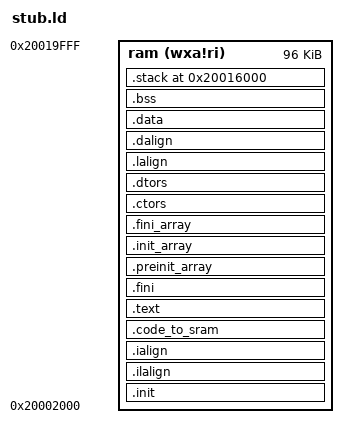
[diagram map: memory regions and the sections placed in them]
OUTPUT_ARCH( "riscv" )

ENTRY( _start )

MEMORY
{
    ram   (wxa!ri) : ORIGIN = 0x20002000, LENGTH = 96K
}


SECTIONS
{
  __stack_size = 16K;

  .init           :
  {
    KEEP (*(SORT_NONE(.init)))
  } >ram

  .ilalign         :
  {
    . = ALIGN(4);
    PROVIDE( _ilm_lma = . );
  } >ram

  .ialign         :
  {
    PROVIDE( _ilm = . );
  } >ram

  _sicode = LOADADDR(.code_to_sram);
  .code_to_sram :
  {
    . = ALIGN(4);
    _scode = .;
    _ecode = .;
  } >ram

  .text           :
  {
    *(.rodata .rodata.*)
    *(.text.unlikely .text.unlikely.*)
    *(.text.startup .text.startup.*)
    *(.text .text.*)
    *(.gnu.linkonce.t.*)
    *(.srodata .srodata.*)
  } >ram

  .fini           :
  {
    KEEP (*(SORT_NONE(.fini)))
  } >ram

  . = ALIGN(4);

  PROVIDE (__etext = .);
  PROVIDE (_etext = .);/*0x80022c8*/
  PROVIDE (etext = .);/*0x80022c8*/
  PROVIDE( _eilm = . );

  .preinit_array  :
  {
    PROVIDE_HIDDEN (__preinit_array_start = .);
    KEEP (*(.preinit_array))
    PROVIDE_HIDDEN (__preinit_array_end = .);
  } >ram

  .init_array     :
  {
    PROVIDE_HIDDEN (__init_array_start = .);
    KEEP (*(SORT_BY_INIT_PRIORITY(.init_array.*) SORT_BY_INIT_PRIORITY(.ctors.*)))
    KEEP (*(.init_array EXCLUDE_FILE (*crtbegin.o *crtbegin?.o *crtend.o *crtend?.o ) .ctors))
    PROVIDE_HIDDEN (__init_array_end = .);
  } >ram

  .fini_array     :
  {
    PROVIDE_HIDDEN (__fini_array_start = .);
    KEEP (*(SORT_BY_INIT_PRIORITY(.fini_array.*) SORT_BY_INIT_PRIORITY(.dtors.*)))
    KEEP (*(.fini_array EXCLUDE_FILE (*crtbegin.o *crtbegin?.o *crtend.o *crtend?.o ) .dtors))
    PROVIDE_HIDDEN (__fini_array_end = .);
  } >ram

  .ctors          :
  {
    /* gcc uses crtbegin.o to find the start of
       the constructors, so we make sure it is
       first.  Because this is a wildcard, it
       doesn't matter if the user does not
       actually link against crtbegin.o; the
       linker won't look for a file to match a
       wildcard.  The wildcard also means that it
       doesn't matter which directory crtbegin.o
       is in.  */
    KEEP (*crtbegin.o(.ctors))
    KEEP (*crtbegin?.o(.ctors))
    /* We don't want to include the .ctor section from
       the crtend.o file until after the sorted ctors.
       The .ctor section from the crtend file contains the
       end of ctors marker and it must be last */
    KEEP (*(EXCLUDE_FILE (*crtend.o *crtend?.o ) .ctors))
    KEEP (*(SORT(.ctors.*)))
    KEEP (*(.ctors))
  } >ram

  .dtors          :
  {
    KEEP (*crtbegin.o(.dtors))
    KEEP (*crtbegin?.o(.dtors))
    KEEP (*(EXCLUDE_FILE (*crtend.o *crtend?.o ) .dtors))
    KEEP (*(SORT(.dtors.*)))
    KEEP (*(.dtors))
  } >ram

    . = ALIGN(4);
    PROVIDE( _eilm = . );

  .lalign         :
  {
    . = ALIGN(4);
    PROVIDE( _data_lma = . );
  } >ram

  .dalign         :
  {
    . = ALIGN(4);
    PROVIDE( _data = . );
  } >ram


  .data          :
  {
    *(.rdata)

    *(.gnu.linkonce.r.*)
    *(.data .data.*)
    *(.gnu.linkonce.d.*)
    . = ALIGN(8);
    PROVIDE( __global_pointer$ = . + 0x800);
    *(.sdata .sdata.*)
    *(.gnu.linkonce.s.*)
    . = ALIGN(8);
  } >ram

  . = ALIGN(4);
  PROVIDE( _edata = . );
  PROVIDE( edata = . );

  PROVIDE( _fbss = . ); /*0X200052A0  0X200002A0*/
  PROVIDE( __bss_start = . );
  .bss            :
  {
    *(.sbss*)
    *(.gnu.linkonce.sb.*)
    *(.bss .bss.*)
    *(.gnu.linkonce.b.*)
    *(COMMON)
    . = ALIGN(4);
  } >ram

  . = ALIGN(8);
  PROVIDE( _end = . ); /*0X2000,0340*/
  PROVIDE( end = . );

  .stack ORIGIN(ram) + LENGTH(ram) - __stack_size :
  {
    PROVIDE( _heap_end = . );
    . = __stack_size;
    PROVIDE( _sp = . );
  } >ram
}
